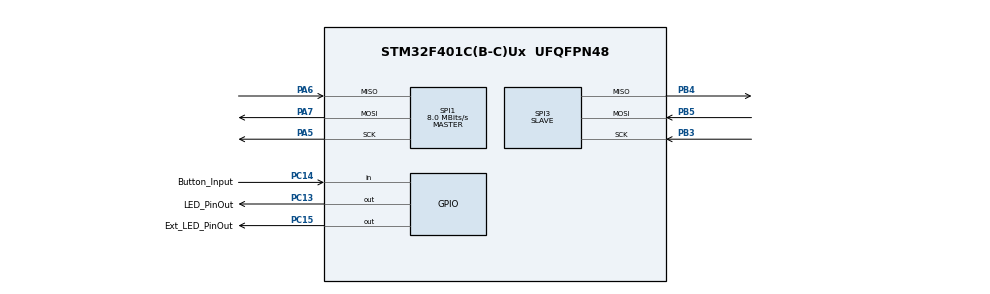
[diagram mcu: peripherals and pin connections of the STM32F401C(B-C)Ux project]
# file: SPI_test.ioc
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Mcu.Family=STM32F4
Mcu.Name=STM32F401C(B-C)Ux
Mcu.Package=UFQFPN48
NVIC.PriorityGroup=NVIC_PRIORITYGROUP_4
NVIC.SPI3_IRQn=true\:0\:0\:false\:false\:true\:true\:false\:true
NVIC.TIM1_UP_TIM10_IRQn=true\:2\:0\:true\:false\:true\:true\:false\:true
PA13.Mode=Serial_Wire
PA13.Signal=SYS_JTMS-SWDIO
PA14.Mode=Serial_Wire
PA14.Signal=SYS_JTCK-SWCLK
PA5.Mode=Full_Duplex_Master
PA5.Signal=SPI1_SCK
PA6.Mode=Full_Duplex_Master
PA6.Signal=SPI1_MISO
PA7.Mode=Full_Duplex_Master
PA7.Signal=SPI1_MOSI
PB3.Mode=Full_Duplex_Slave
PB3.Signal=SPI3_SCK
PB4.Mode=Full_Duplex_Slave
PB4.Signal=SPI3_MISO
PB5.Mode=Full_Duplex_Slave
PB5.Signal=SPI3_MOSI
PC13-ANTI_TAMP.GPIO_Label=LED_PinOut
PC13-ANTI_TAMP.Signal=GPIO_Output
PC14-OSC32_IN.GPIO_Label=Button_Input
PC14-OSC32_IN.GPIO_Mode=GPIO_MODE_INPUT
PC14-OSC32_IN.GPIO_PuPd=GPIO_PULLUP
PC14-OSC32_IN.Signal=GPIO_Input
PC15-OSC32_OUT.GPIO_Label=Ext_LED_PinOut
PC15-OSC32_OUT.Signal=GPIO_Output
ProjectManager.HeapSize=0x200
ProjectManager.StackSize=0x400
ProjectManager.TargetToolchain=EWARM V7
RCC.48MHZClocksFreq_Value=48000000
RCC.AHBFreq_Value=16000000
RCC.APB1Freq_Value=16000000
RCC.APB1TimFreq_Value=16000000
RCC.APB2Freq_Value=16000000
RCC.APB2TimFreq_Value=16000000
RCC.CortexFreq_Value=16000000
RCC.HCLKFreq_Value=16000000
RCC.HSE_VALUE=25000000
RCC.HSI_VALUE=16000000
RCC.LSE_VALUE=32768
RCC.SYSCLKFreq_VALUE=16000000
RCC.VCOOutputFreq_Value=192000000
SPI1.CalculateBaudRate=8.0 MBits/s
SPI1.Direction=SPI_DIRECTION_2LINES
SPI1.Mode=SPI_MODE_MASTER
SPI1.VirtualType=VM_MASTER
SPI3.Direction=SPI_DIRECTION_2LINES
SPI3.Mode=SPI_MODE_SLAVE
SPI3.VirtualType=VM_SLAVE
TIM10.Period=10000-1
TIM10.Prescaler=16-1
VP_TIM10_VS_ClockSourceINT.Mode=Enable_Timer
board=custom

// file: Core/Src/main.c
/* USER CODE BEGIN Header */
/**
  ******************************************************************************
  * @file           : main.c
  * @brief          : Main program body
  ******************************************************************************
  * @attention
  *
  * Copyright (c) 2025 STMicroelectronics.
  * All rights reserved.
  *
  * This software is licensed under terms that can be found in the LICENSE file
  * in the root directory of this software component.
  * If no LICENSE file comes with this software, it is provided AS-IS.
  *
  ******************************************************************************
  */
/* USER CODE END Header */
#include "main.h"
#include "spi.h"
#include "tim.h"
#include "gpio.h"

/* USER CODE BEGIN Includes */
#include "input.h"
#include "driverM.h"
/* USER CODE END Includes */

void SystemClock_Config(void);

int main(void)
{

  /* MCU Configuration--------------------------------------------------------*/

  /* Reset of all peripherals, Initializes the Flash interface and the Systick. */
  LL_APB2_GRP1_EnableClock(LL_APB2_GRP1_PERIPH_SYSCFG);
  LL_APB1_GRP1_EnableClock(LL_APB1_GRP1_PERIPH_PWR);

  /* System interrupt init*/
  NVIC_SetPriorityGrouping(NVIC_PRIORITYGROUP_4);

  /* SysTick_IRQn interrupt configuration */
  NVIC_SetPriority(SysTick_IRQn, NVIC_EncodePriority(NVIC_GetPriorityGrouping(),15, 0));

  /* Configure the system clock */
  SystemClock_Config();

  /* Initialize all configured peripherals */
  MX_GPIO_Init();
  MX_SPI1_Init();
  MX_SPI3_Init();
  MX_TIM10_Init();
  /* USER CODE BEGIN 2 */
  TIM10->CR1 |= 0x0001;
  TIM10->DIER |= 0x0001;

  SPI3->CR2 |= 0x40;
  SPI_Start(SPI1);
  SPI_Start(SPI3);

  /* USER CODE END 2 */

  /* Infinite loop */
  while (1)
  {

  }
}

void SystemClock_Config(void)
{
  LL_FLASH_SetLatency(LL_FLASH_LATENCY_0);
  while(LL_FLASH_GetLatency()!= LL_FLASH_LATENCY_0)
  {
  }
  LL_PWR_SetRegulVoltageScaling(LL_PWR_REGU_VOLTAGE_SCALE2);
  LL_RCC_HSI_SetCalibTrimming(16);
  LL_RCC_HSI_Enable();

   /* Wait till HSI is ready */
  while(LL_RCC_HSI_IsReady() != 1)
  {

  }
  LL_RCC_SetAHBPrescaler(LL_RCC_SYSCLK_DIV_1);
  LL_RCC_SetAPB1Prescaler(LL_RCC_APB1_DIV_1);
  LL_RCC_SetAPB2Prescaler(LL_RCC_APB2_DIV_1);
  LL_RCC_SetSysClkSource(LL_RCC_SYS_CLKSOURCE_HSI);

   /* Wait till System clock is ready */
  while(LL_RCC_GetSysClkSource() != LL_RCC_SYS_CLKSOURCE_STATUS_HSI)
  {

  }
  LL_Init1msTick(16000000);
  LL_SetSystemCoreClock(16000000);
  LL_RCC_SetTIMPrescaler(LL_RCC_TIM_PRESCALER_TWICE);
}

void Error_Handler(void)
{
  __disable_irq();
  while (1)
  {
  }
}
